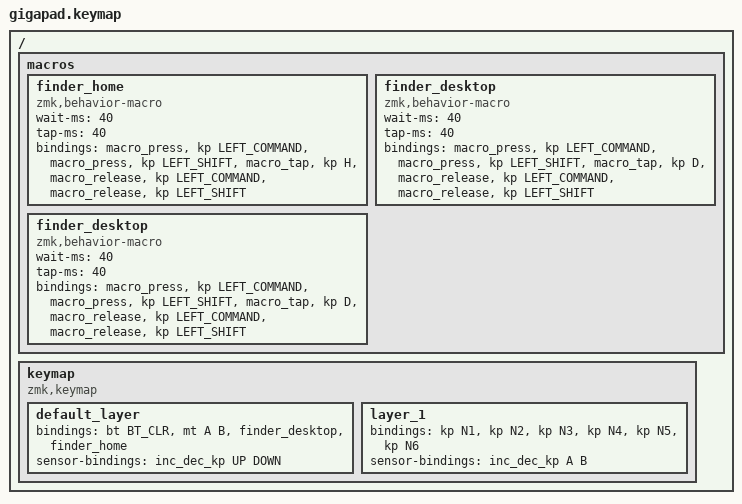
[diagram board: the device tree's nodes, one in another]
#include <behaviors.dtsi>
#include <dt-bindings/zmk/bt.h>
#include <dt-bindings/zmk/keys.h>

/ {
    macros {
        finder_home: finder_home {
            compatible = "zmk,behavior-macro";
            #binding-cells = <0>;
            wait-ms = <40>;
            tap-ms = <40>;
            bindings =
                <&macro_press>,
                <&kp LEFT_COMMAND>,
                <&macro_press>,
                <&kp LEFT_SHIFT>,
                <&macro_tap>,
                <&kp H>,
                <&macro_release>,
                <&kp LEFT_COMMAND>,
                <&macro_release>,
                <&kp LEFT_SHIFT>;
        };

        finder_desktop: finder_desktop {
            compatible = "zmk,behavior-macro";
            #binding-cells = <0>;
            wait-ms = <40>;
            tap-ms = <40>;
            bindings =
                <&macro_press>,
                <&kp LEFT_COMMAND>,
                <&macro_press>,
                <&kp LEFT_SHIFT>,
                <&macro_tap>,
                <&kp D>,
                <&macro_release>,
                <&kp LEFT_COMMAND>,
                <&macro_release>,
                <&kp LEFT_SHIFT>;
        };

        finder_desktop: finder_desktop {
            compatible = "zmk,behavior-macro";
            #binding-cells = <0>;
            wait-ms = <40>;
            tap-ms = <40>;
            bindings =
                <&macro_press>,
                <&kp LEFT_COMMAND>,
                <&macro_press>,
                <&kp LEFT_SHIFT>,
                <&macro_tap>,
                <&kp D>,
                <&macro_release>,
                <&kp LEFT_COMMAND>,
                <&macro_release>,
                <&kp LEFT_SHIFT>;
        };

        finder_desktop: finder_desktop {
            compatible = "zmk,behavior-macro";
            #binding-cells = <0>;
            wait-ms = <40>;
            tap-ms = <40>;
            bindings =
                <&macro_press>,
                <&kp LEFT_COMMAND>,
                <&macro_press>,
                <&kp LEFT_SHIFT>,
                <&macro_tap>,
                <&kp D>,
                <&macro_release>,
                <&kp LEFT_COMMAND>,
                <&macro_release>,
                <&kp LEFT_SHIFT>;
        };

        finder_desktop: finder_desktop {
            compatible = "zmk,behavior-macro";
            #binding-cells = <0>;
            wait-ms = <40>;
            tap-ms = <40>;
            bindings =
                <&macro_press>,
                <&kp LEFT_COMMAND>,
                <&macro_press>,
                <&kp LEFT_SHIFT>,
                <&macro_tap>,
                <&kp D>,
                <&macro_release>,
                <&kp LEFT_COMMAND>,
                <&macro_release>,
                <&kp LEFT_SHIFT>;
        };
    };

    keymap {
        compatible = "zmk,keymap";

        default_layer {
            bindings = <
&bt BT_CLR  &mt A B  &finder_desktop  &finder_home
            >;

            sensor-bindings = <&inc_dec_kp UP DOWN>;
        };

        layer_1 {
            bindings = <
&kp N1  &kp N2  &kp N3  &kp N4  &kp N5  &kp N6
            >;

            sensor-bindings = <&inc_dec_kp A B>;
        };
    };
};
